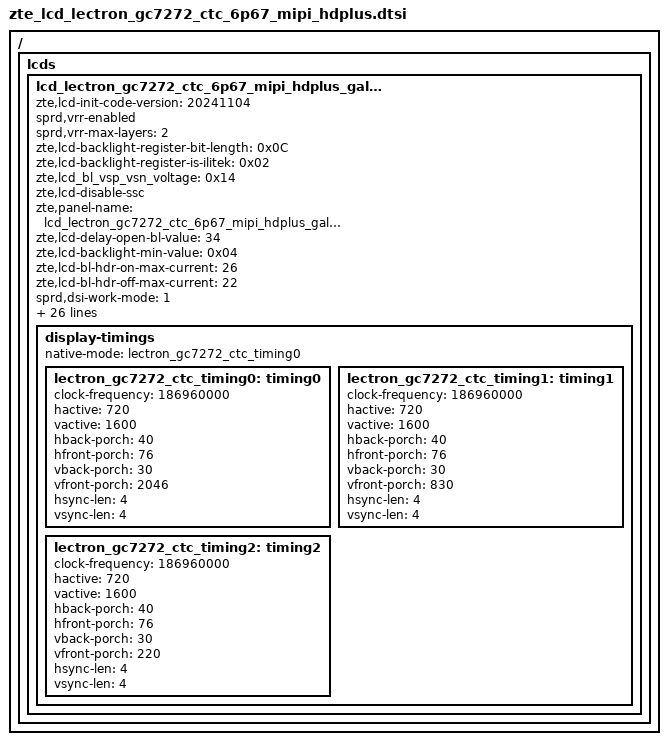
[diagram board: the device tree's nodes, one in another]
/ {
	fragment {
		target-path = "/";
		__overlay__ {
			lcds {
				lcd_lectron_gc7272_ctc_6p67_mipi_hdplus_galaxycore: lcd_lectron_gc7272_ctc_6p67_mipi_hdplus_galaxycore {
					zte,lcd-init-code-version = "20241104";
					sprd,vrr-enabled;
					sprd,vrr-max-layers = <2>;
					zte,lcd-backlight-register-bit-length = <0x0C>;
					zte,lcd-backlight-register-is-ilitek = <0x02>;/*51h=0xff0f*/
					zte,lcd_bl_vsp_vsn_voltage = <0x14>;
					zte,lcd-disable-ssc;
					zte,panel-name = "lcd_lectron_gc7272_ctc_6p67_mipi_hdplus_galaxycore";
					zte,lcd-delay-open-bl-value = <34>;
					zte,lcd-backlight-min-value = <0x04>;
					zte,lcd-bl-hdr-on-max-current = <26>;
					zte,lcd-bl-hdr-off-max-current = <22>;

					sprd,dsi-work-mode = <1>;
					sprd,dsi-lane-number = <4>;
					sprd,dsi-color-format = "rgb888";

					sprd,dpi-clk-div = <6>;
					sprd,video-lp-cmd-enable = <1>;
					sprd,hporch-lp-disable = <1>;

					sprd,phy-bit-clock = <1121760>;
					sprd,phy-escape-clock = <20000>;/* kHz */

					sprd,width-mm = <6955>;
					sprd,height-mm = <15456>;

					sprd,esd-check-enable = <1>;/* 0:close , 1:open */
					sprd,esd-check-mode = <1>;/* 0:REG ,1:TE  */
					sprd,esd-check-period = <2000>;
					sprd,esd-check-register = <0x0A>;
					sprd,esd-check-value = <0x9C>;

					sprd,dphy-taget-val = <5>;

					sprd,reset-on-sequence = <1 5>, <0 5>, <1 5>, <0 5>, <1 5>, <0 5>, <1 5>, <0 5>, <1 30>;
					sprd,reset-off-sequence = <1 20>;

		sprd,initial-command = [
39 00 00 04 FF 55 AA 66
15 00 00 02 FF 10
15 00 00 02 FB 00
15 00 00 02 FF 20
15 00 00 02 FB 00
15 00 00 02 FF 21
15 00 00 02 FB 00
15 00 00 02 FF 22
15 00 00 02 FB 00
15 00 00 02 FF 23
15 00 00 02 FB 00
15 00 00 02 FF 24
15 00 00 02 FB 00
15 00 00 02 FF 25
15 00 00 02 FB 00
15 00 00 02 FF 27
15 00 00 02 FB 00
15 00 00 02 FF 26
15 00 00 02 FB 00
15 00 00 02 FF 28
15 00 00 02 FB 00
15 00 00 02 FF A3
15 00 00 02 FB 00
15 00 00 02 FF B3
15 00 00 02 FB 00
15 00 00 02 FF 20
15 00 00 02 2D 55
15 00 00 02 A3 16
15 00 00 02 A7 16
15 00 00 02 AB 16
15 00 00 02 AF 16
15 00 00 02 FF B3
15 00 00 02 4E 44
15 00 00 02 FF B3
15 00 00 02 3F 37
15 00 00 02 50 10
15 00 00 02 FF 20
15 00 00 02 29 E0
15 00 00 02 20 84
15 00 00 02 21 00
15 00 00 02 22 80
15 00 00 02 2E 00
15 00 00 02 FF A3
15 00 00 02 58 AA
15 00 00 02 FF 26
15 00 00 02 43 00
15 00 00 02 FF 22
15 00 00 02 0E 33
15 00 00 02 0C 01
15 00 00 02 0B 56
15 00 00 02 FF 28
15 00 00 02 7D 1F
15 00 00 02 7B 40
15 00 00 02 FF B3
15 00 00 02 47 01
15 00 00 02 FF 22
15 00 00 02 0D 02
15 00 00 02 FF B3
15 00 00 02 42 05
15 00 00 02 44 52
15 00 00 02 FF 22
15 00 00 02 E4 00
15 00 00 02 01 06
15 00 00 02 02 40
15 00 00 02 03 00
15 00 00 02 FF 20
15 00 00 02 C7 00
15 00 00 02 C8 7c
15 00 00 02 C9 00
15 00 00 02 CA 7c
15 00 00 02 B7 00
15 00 00 02 B8 22
15 00 00 02 B9 01
15 00 00 02 BA 0e
15 00 00 02 D4 02
15 00 00 02 FF 22
15 00 00 02 83 07
15 00 00 02 84 00
15 00 00 02 8B cf
15 00 00 02 8C 00
15 00 00 02 93 08
15 00 00 02 94 00
15 00 00 02 9B cf
15 00 00 02 9C 00
15 00 00 02 FF 28
15 00 00 02 01 18
15 00 00 02 02 19
15 00 00 02 03 1A
15 00 00 02 04 1A
15 00 00 02 05 25
15 00 00 02 06 1E
15 00 00 02 07 1f
15 00 00 02 08 25
15 00 00 02 09 25
15 00 00 02 0A 09
15 00 00 02 0B 0B
15 00 00 02 0C 0D
15 00 00 02 0D 0F
15 00 00 02 0E 11
15 00 00 02 0F 13
15 00 00 02 10 01
15 00 00 02 11 03
15 00 00 02 12 05
15 00 00 02 13 25
15 00 00 02 14 25
15 00 00 02 15 25
15 00 00 02 16 25
15 00 00 02 17 18
15 00 00 02 18 19
15 00 00 02 19 1A
15 00 00 02 1A 25
15 00 00 02 1B 1A
15 00 00 02 1C 1E
15 00 00 02 1D 1f
15 00 00 02 1E 25
15 00 00 02 1F 25
15 00 00 02 20 08
15 00 00 02 21 0A
15 00 00 02 22 0C
15 00 00 02 23 0E
15 00 00 02 24 10
15 00 00 02 25 12
15 00 00 02 26 00
15 00 00 02 27 02
15 00 00 02 28 04
15 00 00 02 29 25
15 00 00 02 2A 25
15 00 00 02 2B 25
15 00 00 02 2D 25
15 00 00 02 30 00
15 00 00 02 31 55
15 00 00 02 32 00
15 00 00 02 33 05
15 00 00 02 34 00
15 00 00 02 35 55
15 00 00 02 36 00
15 00 00 02 37 55
15 00 00 02 38 00
15 00 00 02 39 01
15 00 00 02 2F 48
15 00 00 02 FF 21
15 00 00 02 7E 0F
15 00 00 02 7F 25
15 00 00 02 8B 25
15 00 00 02 97 25
15 00 00 02 A3 25
15 00 00 02 80 0B
15 00 00 02 8C 07
15 00 00 02 98 03
15 00 00 02 81 0B
15 00 00 02 8D 03
15 00 00 02 99 07
15 00 00 02 AF 40
15 00 00 02 B0 40
15 00 00 02 B1 40
15 00 00 02 B2 40
15 00 00 02 2B 00
15 00 00 02 83 04
15 00 00 02 8F 04
15 00 00 02 9B 04
15 00 00 02 D2 60
15 00 00 02 D4 60
15 00 00 02 D6 60
15 00 00 02 D3 6c
15 00 00 02 D5 6c
15 00 00 02 D7 6c
15 00 00 02 87 07
15 00 00 02 93 23
15 00 00 02 9F 02
15 00 00 02 22 07
15 00 00 02 23 23
15 00 00 02 24 02
15 00 00 02 82 B0
15 00 00 02 8E B0
15 00 00 02 9A B0
15 00 00 02 2E 00
15 00 00 02 88 B7
15 00 00 02 89 20
15 00 00 02 8A 23
15 00 00 02 94 B7
15 00 00 02 95 20
15 00 00 02 96 23
15 00 00 02 A0 B7
15 00 00 02 A1 20
15 00 00 02 A2 23
15 00 00 02 45 FF
15 00 00 02 46 B6
15 00 00 02 4C B6
15 00 00 02 52 B6
15 00 00 02 58 B6
15 00 00 02 5E B6
15 00 00 02 64 B6
15 00 00 02 08 00
15 00 00 02 47 11
15 00 00 02 4D 10
15 00 00 02 53 0f
15 00 00 02 59 0e
15 00 00 02 5F 0d
15 00 00 02 65 0c
15 00 00 02 48 0C
15 00 00 02 4E 0D
15 00 00 02 54 0E
15 00 00 02 5A 0F
15 00 00 02 60 10
15 00 00 02 66 11
15 00 00 02 76 40
15 00 00 02 77 40
15 00 00 02 78 40
15 00 00 02 79 40
15 00 00 02 7A 40
15 00 00 02 7B 40
15 00 00 02 E7 60
15 00 00 02 E8 6c
15 00 00 02 E9 60
15 00 00 02 EA 6c
15 00 00 02 EB 60
15 00 00 02 EC 6c
15 00 00 02 ED 60
15 00 00 02 EE 6c
15 00 00 02 F1 60
15 00 00 02 F2 6c
15 00 00 02 F3 60
15 00 00 02 F4 6c
15 00 00 02 BE 03
15 00 00 02 C0 70
15 00 00 02 C1 42
15 00 00 02 BF BB
15 00 00 02 12 E0
15 00 00 02 13 17
15 00 00 02 14 E0
15 00 00 02 15 17
15 00 00 02 C2 8a
15 00 00 02 C6 72
15 00 00 02 29 00
15 00 00 02 B3 E0
15 00 00 02 B4 16
15 00 00 02 BB 77
15 00 00 02 BC 50
15 00 00 02 B5 E0
15 00 00 02 B6 12
15 00 00 02 B7 A7
15 00 00 02 B8 15
15 00 00 02 BB 77
15 00 00 02 BD 54
15 00 00 02 B9 A7
15 00 00 02 BA 11
15 00 00 02 FF 22
15 00 00 02 05 00
15 00 00 02 08 22
15 00 00 02 FF 28
15 00 00 02 3D 52
15 00 00 02 3E 52
15 00 00 02 3F 41
15 00 00 02 40 41
15 00 00 02 45 50
15 00 00 02 46 50
15 00 00 02 47 40
15 00 00 02 48 40
15 00 00 02 4D A2
15 00 00 02 50 2A
15 00 00 02 75 22
15 00 00 02 52 73
15 00 00 02 53 22
15 00 00 02 77 22
15 00 00 02 56 12
15 00 00 02 79 02
15 00 00 02 57 20
15 00 00 02 5A 82
15 00 00 02 5B 82
15 00 00 02 FF 20
15 00 00 02 7E 01
15 00 00 02 70 03
15 00 00 02 71 00
15 00 00 02 72 64
15 00 00 02 73 00
15 00 00 02 74 00
15 00 00 02 75 64
15 00 00 02 76 64
15 00 00 02 77 31
15 00 00 02 78 99
15 00 00 02 79 31
15 00 00 02 7A 99
15 00 00 02 7C 0A
15 00 00 02 7D 0A
15 00 00 02 FF 25
15 00 00 02 85 06
15 00 00 02 86 00
15 00 00 02 87 64
15 00 00 02 88 00
15 00 00 02 89 64
15 00 00 02 8A 64
15 00 00 02 8B 64
15 00 00 02 8C 18
15 00 00 02 8D 24
15 00 00 02 8E 18
15 00 00 02 8F 24
15 00 00 02 90 00
15 00 00 02 91 03
15 00 00 02 92 03
15 00 00 02 FF 23
15 00 00 02 29 03
39 00 00 11 01 00 24 00 47 00 57 00 77 00 90 00 A3 00 B2 00 BF
39 00 00 11 02 00 D5 01 0B 01 2E 01 66 01 90 01 D5 02 12 02 14
39 00 00 11 03 02 54 02 A4 02 D5 03 10 03 38 03 68 03 6C 03 83
39 00 00 0D 04 03 8B 03 A7 03 B2 03 cB 03 ef 03 FF
39 00 00 11 0D 00 24 00 47 00 57 00 77 00 90 00 A3 00 B2 00 BF
39 00 00 11 0E 00 D5 01 0B 01 2E 01 66 01 90 01 D5 02 12 02 14
39 00 00 11 0F 02 54 02 A4 02 D5 03 10 03 38 03 68 03 6C 03 83
39 00 00 0D 10 03 8B 03 A7 03 B2 03 cB 03 ef 03 FF
15 00 00 02 F0 01
15 00 00 02 2D 65
15 00 00 02 2E 00
15 00 00 02 32 01
15 00 00 02 33 2d
15 00 00 02 FF 20
15 00 00 02 15 13
15 00 00 02 16 88
15 00 00 02 17 0f
15 00 00 02 18 a0
15 00 00 02 19 09
15 00 00 02 1A FC
15 00 00 02 1B 07
15 00 00 02 1C d0
15 00 00 02 FF 10
39 00 00 03 51 00 00
15 00 00 02 53 2c
15 00 00 02 55 00
15 00 00 02 36 08
15 00 00 02 69 01
15 00 00 02 35 00
15 00 00 02 BA 03
15 00 00 02 FF 20
15 00 00 02 F7 f3
15 00 00 02 F8 00
15 00 00 02 FF 20
15 00 00 02 24 89
15 00 00 02 FF 20
15 00 00 02 B1 10
15 00 00 02 AD 10
15 00 00 02 23 1A
15 00 00 02 FF 10
05 78 00 01 11
05 32 00 01 29
		];

					sprd,sleep-in-command = [
						39 00 00 04 FF 55 AA 66
						15 00 00 02 FF 10
						15 32 00 02 28 00
						15 78 00 02 10 00
						15 14 00 02 4F 01
						];
					sprd,sleep-in-command2 = [
						39 00 00 04 FF 55 AA 66
						15 00 00 02 FF 10
						15 00 00 02 EB 04
						15 32 00 02 28 00
						15 78 00 02 10 00
						];
					sprd,sleep-out-command = [
						05 78 00 01 11
						05 64 00 01 29
						];

					display-timings {
						native-mode = <&lectron_gc7272_ctc_timing0>;
						lectron_gc7272_ctc_timing0: timing0 {/*60hz*/
							clock-frequency = <186960000>;
							hactive = <720>;
 							vactive = <1600>;
							hback-porch = <40>;
							hfront-porch = <76>;
							vback-porch = <30>;
							vfront-porch = <2046>;
							hsync-len = <4>;
 							vsync-len = <4>;
 
 						};
						lectron_gc7272_ctc_timing1: timing1 {/*90hz*/
							clock-frequency = <186960000>;
							hactive = <720>;
							vactive = <1600>;
							hback-porch = <40>;
							hfront-porch = <76>;
							vback-porch = <30>;
							vfront-porch = <830>;
							hsync-len = <4>;
 							vsync-len = <4>;
						};

						 lectron_gc7272_ctc_timing2: timing2 {/*120hz*/
							clock-frequency = <186960000>;
 							hactive = <720>;
 							vactive = <1600>;
							hback-porch = <40>;
							hfront-porch = <76>;
							vback-porch = <30>;
							vfront-porch = <220>;
							hsync-len = <4>;
 							vsync-len = <4>;
 
						};
					};
				};
			};
		};
	};
};
